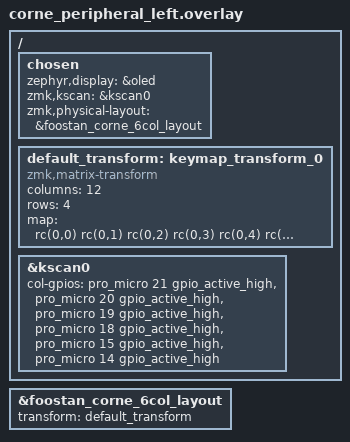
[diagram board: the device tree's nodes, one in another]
/*
 * copyright (c) 2020 pete johanson
 *
 * spdx-license-identifier: mit
 */

#include "corne.dtsi"
#include <layouts/foostan/corne/6column.dtsi>

&foostan_corne_6col_layout {
    transform = <&default_transform>;
};
/ {
    chosen {
       zephyr,display = &oled;
        zmk,kscan = &kscan0;
        zmk,physical-layout = &foostan_corne_6col_layout;
    };

    default_transform: keymap_transform_0 {
        compatible = "zmk,matrix-transform";
        columns = <12>;
        rows = <4>;
// | sw1  | sw2  | sw3  | sw4  | sw5  | sw6  |   | sw6  | sw5  | sw4  | sw3  | sw2  | sw1  |
// | sw7  | sw8  | sw9  | sw10 | sw11 | sw12 |   | sw12 | sw11 | sw10 | sw9  | sw8  | sw7  |
// | sw13 | sw14 | sw15 | sw16 | sw17 | sw18 |   | sw18 | sw17 | sw16 | sw15 | sw14 | sw13 |
//                      | sw19 | sw20 | sw21 |   | sw21 | sw20 | sw19 |
        map = <
rc(0,0) rc(0,1) rc(0,2) rc(0,3) rc(0,4) rc(0,5)  rc(0,6) rc(0,7) rc(0,8) rc(0,9) rc(0,10) rc(0,11)
rc(1,0) rc(1,1) rc(1,2) rc(1,3) rc(1,4) rc(1,5)  rc(1,6) rc(1,7) rc(1,8) rc(1,9) rc(1,10) rc(1,11)
rc(2,0) rc(2,1) rc(2,2) rc(2,3) rc(2,4) rc(2,5)  rc(2,6) rc(2,7) rc(2,8) rc(2,9) rc(2,10) rc(2,11)
                        rc(3,3) rc(3,4) rc(3,5)  rc(3,6) rc(3,7) rc(3,8)
        >;
    };

&kscan0 {
    col-gpios
        = <&pro_micro 21 gpio_active_high>
        , <&pro_micro 20 gpio_active_high>
        , <&pro_micro 19 gpio_active_high>
        , <&pro_micro 18 gpio_active_high>
        , <&pro_micro 15 gpio_active_high>
        , <&pro_micro 14 gpio_active_high>
        ;
};
};
